# PIC32MX170F256B register map
Registers are 32-bit, access not given, reset 0x0 unless marked. A register's access mark holds for its fields unless they carry their own. Offsets are from the block's base; [hi:lo] are bit positions; 'fields as' and 'values as' point back to an identical list.

## OCMP1 — OCMP1 peripheral
Base 0xBF803000
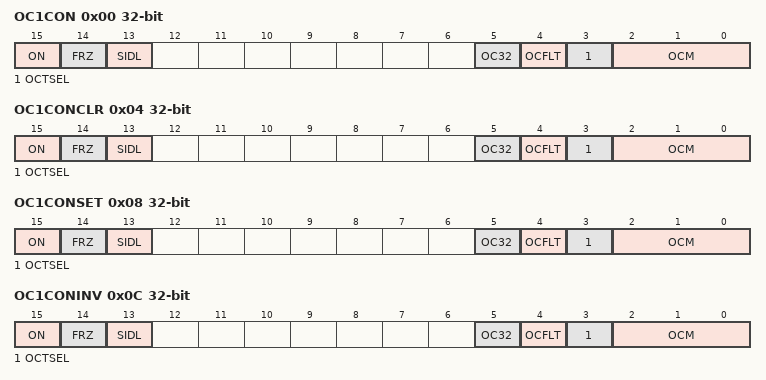
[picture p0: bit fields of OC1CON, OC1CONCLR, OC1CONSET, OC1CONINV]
0x00 OC1CON
  [15] ON, [14] FRZ, [13] SIDL, [5] OC32, [4] OCFLT, [3] OCTSEL, [2:0] OCM
0x04 OC1CONCLR
  fields as OC1CON
0x08 OC1CONSET
  fields as OC1CON
0x0C OC1CONINV
  fields as OC1CON
0x10 OC1R
0x14 OC1RCLR
  [31:0] OC1R
0x18 OC1RSET
  [31:0] OC1R
0x1C OC1RINV
  [31:0] OC1R
0x20 OC1RS
0x24 OC1RSCLR
  [31:0] OC1RS
0x28 OC1RSSET
  [31:0] OC1RS
0x2C OC1RSINV
  [31:0] OC1RS

## OCMP2 — OCMP2 peripheral
Base 0xBF803200
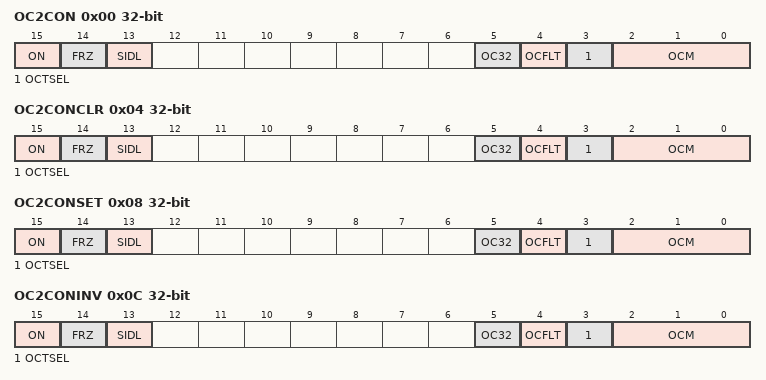
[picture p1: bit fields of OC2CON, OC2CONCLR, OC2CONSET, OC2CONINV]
0x00 OC2CON
  [15] ON, [14] FRZ, [13] SIDL, [5] OC32, [4] OCFLT, [3] OCTSEL, [2:0] OCM
0x04 OC2CONCLR
  fields as OC2CON
0x08 OC2CONSET
  fields as OC2CON
0x0C OC2CONINV
  fields as OC2CON
0x10 OC2R
0x14 OC2RCLR
  [31:0] OC2R
0x18 OC2RSET
  [31:0] OC2R
0x1C OC2RINV
  [31:0] OC2R
0x20 OC2RS
0x24 OC2RSCLR
  [31:0] OC2RS
0x28 OC2RSSET
  [31:0] OC2RS
0x2C OC2RSINV
  [31:0] OC2RS

## OCMP3 — OCMP3 peripheral
Base 0xBF803400
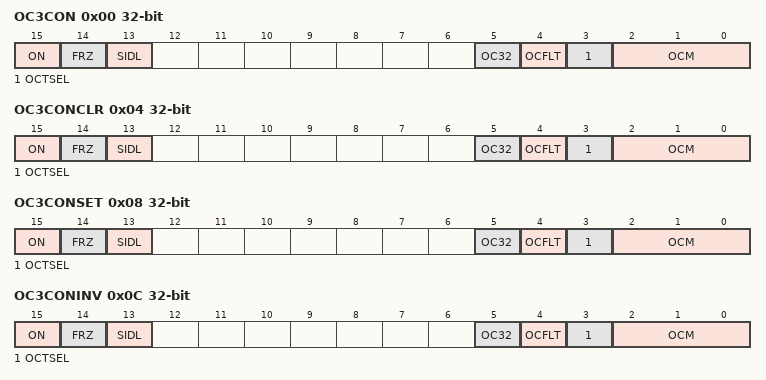
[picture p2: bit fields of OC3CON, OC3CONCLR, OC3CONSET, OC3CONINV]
0x00 OC3CON
  [15] ON, [14] FRZ, [13] SIDL, [5] OC32, [4] OCFLT, [3] OCTSEL, [2:0] OCM
0x04 OC3CONCLR
  fields as OC3CON
0x08 OC3CONSET
  fields as OC3CON
0x0C OC3CONINV
  fields as OC3CON
0x10 OC3R
0x14 OC3RCLR
  [31:0] OC3R
0x18 OC3RSET
  [31:0] OC3R
0x1C OC3RINV
  [31:0] OC3R
0x20 OC3RS
0x24 OC3RSCLR
  [31:0] OC3RS
0x28 OC3RSSET
  [31:0] OC3RS
0x2C OC3RSINV
  [31:0] OC3RS

## OCMP4 — OCMP4 peripheral
Base 0xBF803600
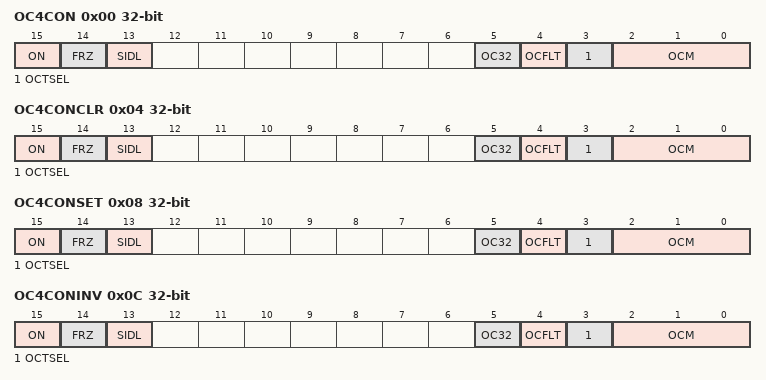
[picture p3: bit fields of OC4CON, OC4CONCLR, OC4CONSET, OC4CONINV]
0x00 OC4CON
  [15] ON, [14] FRZ, [13] SIDL, [5] OC32, [4] OCFLT, [3] OCTSEL, [2:0] OCM
0x04 OC4CONCLR
  fields as OC4CON
0x08 OC4CONSET
  fields as OC4CON
0x0C OC4CONINV
  fields as OC4CON
0x10 OC4R
0x14 OC4RCLR
  [31:0] OC4R
0x18 OC4RSET
  [31:0] OC4R
0x1C OC4RINV
  [31:0] OC4R
0x20 OC4RS
0x24 OC4RSCLR
  [31:0] OC4RS
0x28 OC4RSSET
  [31:0] OC4RS
0x2C OC4RSINV
  [31:0] OC4RS

## OCMP5 — OCMP5 peripheral
Base 0xBF803800
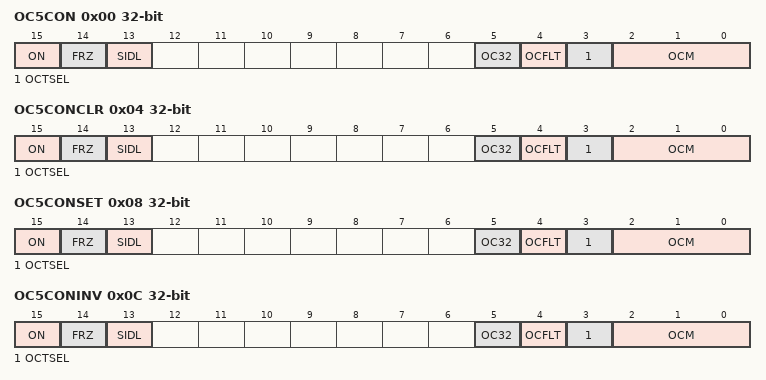
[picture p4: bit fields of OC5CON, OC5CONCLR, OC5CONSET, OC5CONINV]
0x00 OC5CON
  [15] ON, [14] FRZ, [13] SIDL, [5] OC32, [4] OCFLT, [3] OCTSEL, [2:0] OCM
0x04 OC5CONCLR
  fields as OC5CON
0x08 OC5CONSET
  fields as OC5CON
0x0C OC5CONINV
  fields as OC5CON
0x10 OC5R
0x14 OC5RCLR
  [31:0] OC5R
0x18 OC5RSET
  [31:0] OC5R
0x1C OC5RINV
  [31:0] OC5R
0x20 OC5RS
0x24 OC5RSCLR
  [31:0] OC5RS
0x28 OC5RSSET
  [31:0] OC5RS
0x2C OC5RSINV
  [31:0] OC5RS

## I2C1 — I2C1 peripheral
Base 0xBF805000
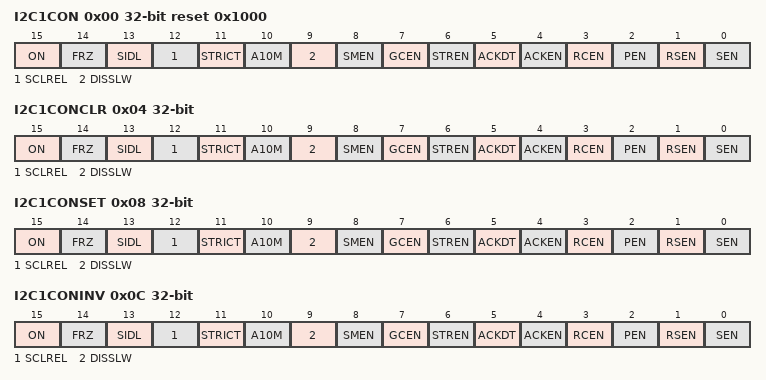
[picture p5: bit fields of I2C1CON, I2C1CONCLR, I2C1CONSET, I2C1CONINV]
0x00 I2C1CON reset 0x1000
  [15] ON, [14] FRZ, [13] SIDL, [12] SCLREL, [11] STRICT, [10] A10M, [9] DISSLW, [8] SMEN, [7] GCEN, [6] STREN, [5] ACKDT, [4] ACKEN, [3] RCEN, [2] PEN, [1] RSEN, [0] SEN
0x04 I2C1CONCLR
  fields as I2C1CON
0x08 I2C1CONSET
  fields as I2C1CON
0x0C I2C1CONINV
  fields as I2C1CON
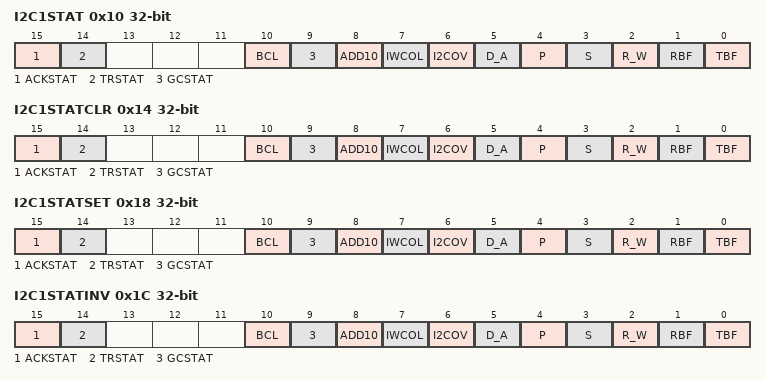
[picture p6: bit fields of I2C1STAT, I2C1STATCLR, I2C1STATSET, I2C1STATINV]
0x10 I2C1STAT
  [15] ACKSTAT, [14] TRSTAT, [10] BCL, [9] GCSTAT, [8] ADD10, [7] IWCOL, [6] I2COV, [5] D_A, [4] P, [3] S, [2] R_W, [1] RBF, [0] TBF
0x14 I2C1STATCLR
  fields as I2C1STAT
0x18 I2C1STATSET
  fields as I2C1STAT
0x1C I2C1STATINV
  fields as I2C1STAT
0x20 I2C1ADD
  [9:0] I2CADD
0x24 I2C1ADDCLR
  [9:0] I2CADD
0x28 I2C1ADDSET
  [9:0] I2CADD
0x2C I2C1ADDINV
  [9:0] I2CADD
0x30 I2C1MSK
  [9:0] I2CMSK
0x34 I2C1MSKCLR
  [9:0] I2CMSK
0x38 I2C1MSKSET
  [9:0] I2CMSK
0x3C I2C1MSKINV
  [9:0] I2CMSK
0x40 I2C1BRG
  [11:0] I2CBRG
0x44 I2C1BRGCLR
  [11:0] I2CBRG
0x48 I2C1BRGSET
  [11:0] I2CBRG
0x4C I2C1BRGINV
  [11:0] I2CBRG
0x50 I2C1TRN
  [7:0] I2CTRN
0x54 I2C1TRNCLR
  [7:0] I2CTRN
0x58 I2C1TRNSET
  [7:0] I2CTRN
0x5C I2C1TRNINV
  [7:0] I2CTRN
0x60 I2C1RCV
  [7:0] I2CRCV

## I2C2 — I2C2 peripheral
Base 0xBF805100
Registers as I2C1 (with I2C1 read as I2C2).

## SPI1 — SPI1 peripheral
Base 0xBF805800
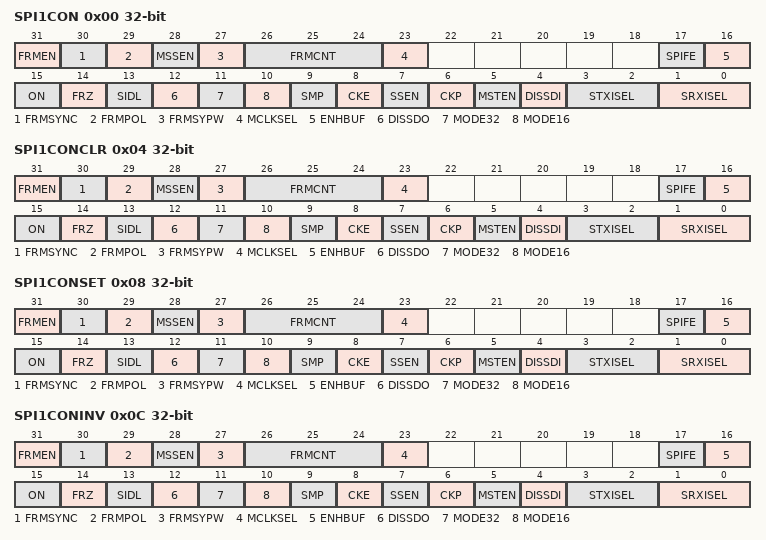
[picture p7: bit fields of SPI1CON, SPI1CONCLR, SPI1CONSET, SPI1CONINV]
0x00 SPI1CON
  [31] FRMEN, [30] FRMSYNC, [29] FRMPOL, [28] MSSEN, [27] FRMSYPW, [26:24] FRMCNT, [23] MCLKSEL, [17] SPIFE, [16] ENHBUF, [15] ON, [14] FRZ, [13] SIDL, [12] DISSDO, [11] MODE32, [10] MODE16, [9] SMP, [8] CKE, [7] SSEN, [6] CKP, [5] MSTEN, [4] DISSDI, [3:2] STXISEL, [1:0] SRXISEL
0x04 SPI1CONCLR
  fields as SPI1CON
0x08 SPI1CONSET
  fields as SPI1CON
0x0C SPI1CONINV
  fields as SPI1CON
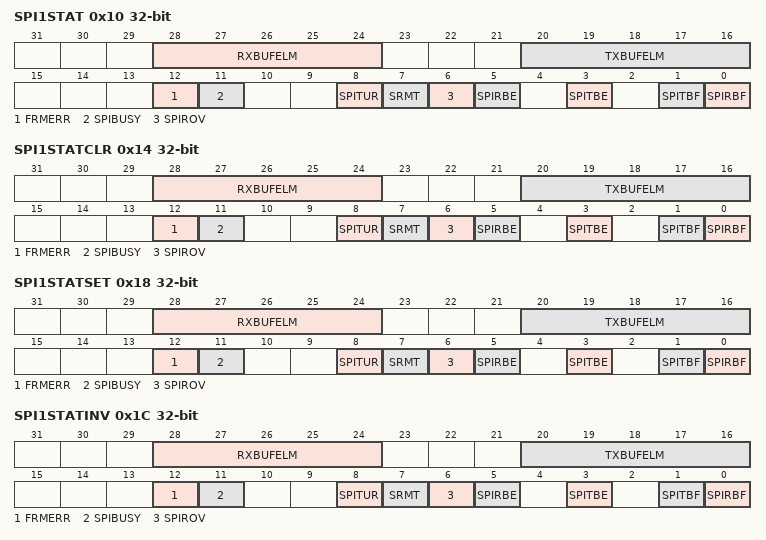
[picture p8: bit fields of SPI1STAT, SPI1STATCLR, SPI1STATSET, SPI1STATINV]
0x10 SPI1STAT
  [28:24] RXBUFELM, [20:16] TXBUFELM, [12] FRMERR, [11] SPIBUSY, [8] SPITUR, [7] SRMT, [6] SPIROV, [5] SPIRBE, [3] SPITBE, [1] SPITBF, [0] SPIRBF
0x14 SPI1STATCLR
  fields as SPI1STAT
0x18 SPI1STATSET
  fields as SPI1STAT
0x1C SPI1STATINV
  fields as SPI1STAT
0x20 SPI1BUF
0x30 SPI1BRG
  [12:0] SPI1BRG
0x34 SPI1BRGCLR
  [12:0] SPI1BRG
0x38 SPI1BRGSET
  [12:0] SPI1BRG
0x3C SPI1BRGINV
  [12:0] SPI1BRG
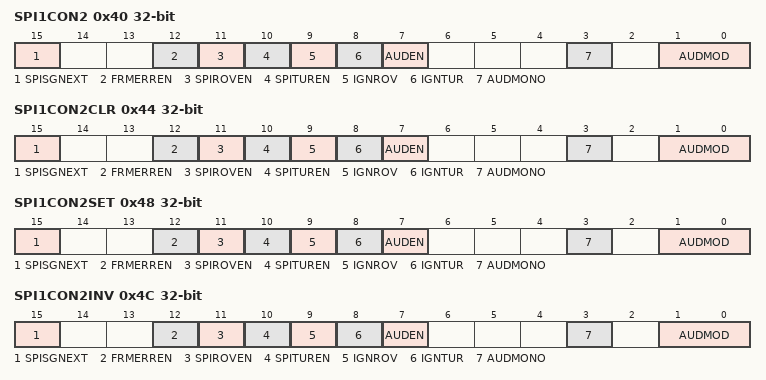
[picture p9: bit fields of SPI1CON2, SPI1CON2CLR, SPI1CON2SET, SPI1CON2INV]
0x40 SPI1CON2
  [15] SPISGNEXT, [12] FRMERREN, [11] SPIROVEN, [10] SPITUREN, [9] IGNROV, [8] IGNTUR, [7] AUDEN, [3] AUDMONO, [1:0] AUDMOD
0x44 SPI1CON2CLR
  fields as SPI1CON2
0x48 SPI1CON2SET
  fields as SPI1CON2
0x4C SPI1CON2INV
  fields as SPI1CON2

## SPI2 — SPI2 peripheral
Base 0xBF805A00
Registers as SPI1 (with SPI1 read as SPI2).
